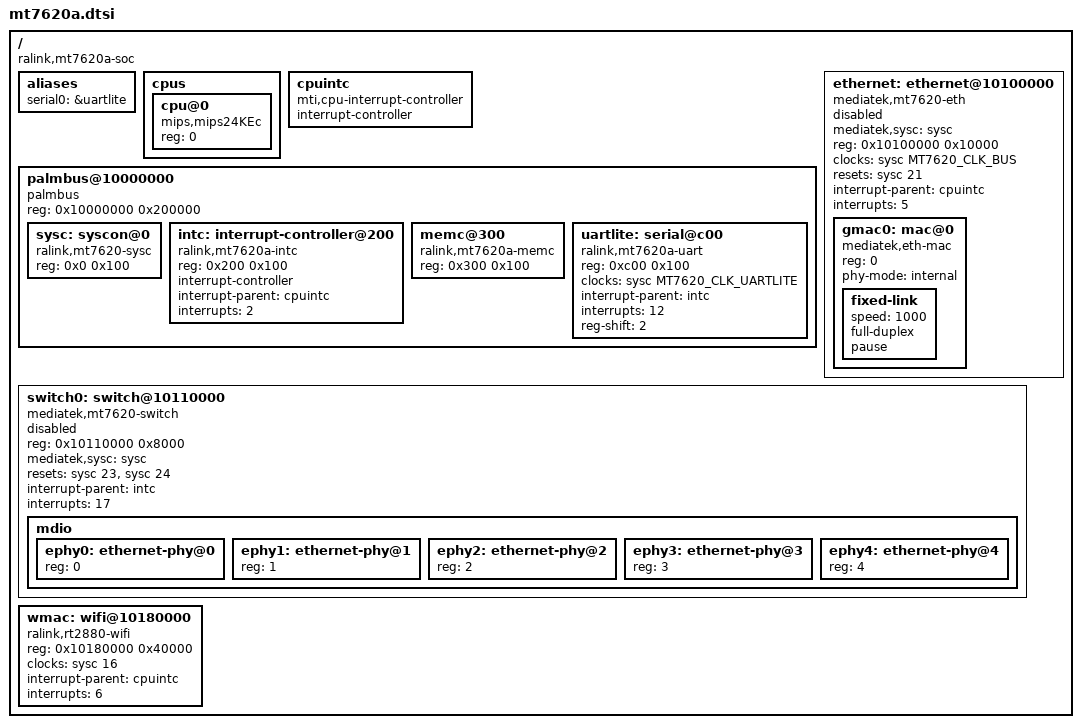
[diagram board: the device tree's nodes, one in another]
// SPDX-License-Identifier: GPL-2.0
#include <dt-bindings/clock/mediatek,mtmips-sysc.h>

/ {
	#address-cells = <1>;
	#size-cells = <1>;
	compatible = "ralink,mt7620a-soc";

	aliases {
		serial0 = &uartlite;
	};

	cpus {
		#address-cells = <1>;
		#size-cells = <0>;
		cpu@0 {
			compatible = "mips,mips24KEc";
			device_type = "cpu";
			reg = <0>;
		};
	};

	cpuintc: cpuintc {
		#address-cells = <0>;
		#interrupt-cells = <1>;
		interrupt-controller;
		compatible = "mti,cpu-interrupt-controller";
	};

	palmbus@10000000 {
		compatible = "palmbus";
		reg = <0x10000000 0x200000>;
		ranges = <0x0 0x10000000 0x200000>;

		#address-cells = <1>;
		#size-cells = <1>;

		sysc: syscon@0 {
			compatible = "ralink,mt7620-sysc", "syscon";
			reg = <0x0 0x100>;
			#clock-cells = <1>;
			#reset-cells = <1>;
		};

		intc: interrupt-controller@200 {
			compatible = "ralink,mt7620a-intc", "ralink,rt2880-intc";
			reg = <0x200 0x100>;

			interrupt-controller;
			#address-cells = <0>;
			#interrupt-cells = <1>;

			interrupt-parent = <&cpuintc>;
			interrupts = <2>;
		};

		memc@300 {
			compatible = "ralink,mt7620a-memc", "ralink,rt3050-memc";
			reg = <0x300 0x100>;
		};

		uartlite: serial@c00 {
			compatible = "ralink,mt7620a-uart", "ralink,rt2880-uart", "ns16550a";
			reg = <0xc00 0x100>;

			clocks = <&sysc MT7620_CLK_UARTLITE>;

			interrupt-parent = <&intc>;
			interrupts = <12>;

			reg-shift = <2>;
		};
	};

	ethernet: ethernet@10100000 {
		compatible = "mediatek,mt7620-eth";
		mediatek,sysc = <&sysc>;
		reg = <0x10100000 0x10000>;
		clocks = <&sysc MT7620_CLK_BUS>;
		clock-names = "fe";
		resets = <&sysc 21>;
		reset-names = "fe";
		interrupt-parent = <&cpuintc>;
		interrupts = <5>;
		#address-cells = <1>;
		#size-cells = <0>;
		status = "disabled";

		gmac0: mac@0 {
			compatible = "mediatek,eth-mac";
			reg = <0>;
			phy-mode = "internal";

			fixed-link {
				speed = <1000>;
				full-duplex;
				pause;
			};
		};
	};

	switch0: switch@10110000 {
		compatible = "mediatek,mt7620-switch";
		reg = <0x10110000 0x8000>;
		mediatek,sysc = <&sysc>;
		resets = <&sysc 23>, <&sysc 24>;
		reset-names = "esw", "ephy";
		interrupt-parent = <&intc>;
		interrupts = <17>;
		status = "disabled";

		mdio {
			#address-cells = <1>;
			#size-cells = <0>;

			ephy0: ethernet-phy@0 {
				reg = <0>;
			};

			ephy1: ethernet-phy@1 {
				reg = <1>;
			};

			ephy2: ethernet-phy@2 {
				reg = <2>;
			};

			ephy3: ethernet-phy@3 {
				reg = <3>;
			};

			ephy4: ethernet-phy@4 {
				reg = <4>;
			};
		};
	};

	wmac: wifi@10180000 {
		compatible = "ralink,rt2880-wifi";
		reg = <0x10180000 0x40000>;

		clocks = <&sysc 16>;

		interrupt-parent = <&cpuintc>;
		interrupts = <6>;
	};
};
